# RSL15 register map
Vendor: ONSemiconductor; Series: RSL15 Series; File version: 1.0
CPU: CM33 r0p4, little endian, MPU, FPU, 3 interrupt priority bits
Registers are 32-bit, read-write, reset 0x0 unless marked. A register's access mark holds for its fields unless they carry their own. Offsets are from the block's base; [hi:lo] are bit positions.

## I2C0 — I2C Interface
Base 0x40000D00
Same registers: I2C1 0x40000E00
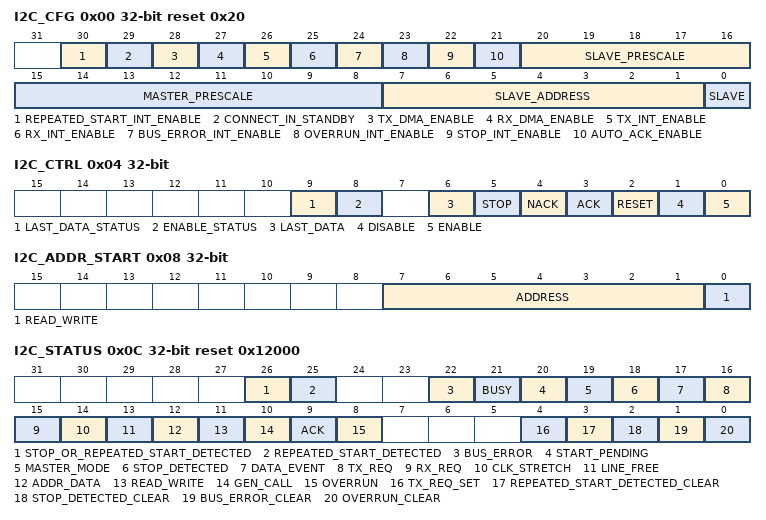
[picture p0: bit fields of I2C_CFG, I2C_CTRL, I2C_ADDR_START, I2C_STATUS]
0x00 I2C_CFG reset 0x20 — Configuration Register
  [30] REPEATED_START_INT_ENABLE — Configure whether repeated start interrupts will be generated by the I2C interface for active transactions in slave mode
    0=I2C_REPEATED_START_INT_DISABLE (Repeated start interrupts are not generated); 1=I2C_REPEATED_START_INT_ENABLE (A repeated start interrupt is generated when a repeated start condition occurs during an active transaction in slave mode)
  [29] CONNECT_IN_STANDBY — Control if the I2C lines are connected when running on the standby clock
    0=I2C_DISCONNECT_IN_STANDBY (Disconnect the I2C lines when running on standby clock); 1=I2C_CONNECT_IN_STANDBY (Keep the I2C lines connected when running on standby clock)
  [28] TX_DMA_ENABLE — Enable/disable the TX DMA request
    0=I2C_TX_DMA_DISABLE (No TX DMA request is generated); 1=I2C_TX_DMA_ENABLE (A TX DMA request is generated when new data is requested by the I2C interface)
  [27] RX_DMA_ENABLE — Enable/disable the RX DMA request
    0=I2C_RX_DMA_DISABLE (No RX DMA request is generated); 1=I2C_RX_DMA_ENABLE (An RX DMA request is generated when new data is received by the I2C interface)
  [26] TX_INT_ENABLE — Enable/disable the TX interrupt
    0=I2C_TX_INT_DISABLE (No TX interrupt is raised); 1=I2C_TX_INT_ENABLE (A TX interrupt is raised when new data is requested by the I2C interface)
  [25] RX_INT_ENABLE — Enable/disable the RX interrupt
    0=I2C_RX_INT_DISABLE (No RX interrupt is raised); 1=I2C_RX_INT_ENABLE (An RX interrupt is raised when new data is received by the I2C interface)
  [24] BUS_ERROR_INT_ENABLE — Enable/disable the bus error interrupt
    0=I2C_BUS_ERROR_INT_DISABLE (No bus error interrupt is raised when an overrun is detected); 1=I2C_BUS_ERROR_INT_ENABLE (A bus error interrupt is raised when an overrun occurs on the I2C interface)
  [23] OVERRUN_INT_ENABLE — Enable/disable the overrun interrupt
    0=I2C_OVERRUN_INT_DISABLE (No overrun interrupt is raised when an overrun is detected); 1=I2C_OVERRUN_INT_ENABLE (An overrun interrupt is raised when an overrun occurs on the I2C interface)
  [22] STOP_INT_ENABLE — Configure whether stop interrupts will be generated by the I2C interface
    0=I2C_STOP_INT_DISABLE (Stop interrupts are not generated); 1=I2C_STOP_INT_ENABLE (A stop interrupt is generated when a stop condition occurs for an active transaction)
  [21] AUTO_ACK_ENABLE — Select whether acknowledgement is automatically generated or not
    0=I2C_AUTO_ACK_DISABLE (Require manual acknowledgement of all I2C interface transfers); 1=I2C_AUTO_ACK_ENABLE (Use automatic acknowledgement for I2C interface transfers)
  [20:16] SLAVE_PRESCALE — Controls the number of SYSCLK wait cycles in case of clock streching (in slave mode) between the moment the data is put on the SDA line and the SCL line is released.
    0=I2C_SLAVE_PRESCALE_1 (Slave Standard-mode: at least 250 ns +10 percent data set-up time with SYSCLK = 3 MHz; Slave Fast-mode: at least 100 ns +10 percent data set-up time with SYSCLK = 3, 4, 5, 8 MHz; Slave Fast-mode Plus: at least 50 ns +10 percent data set-up time with SYSCLK = 3, 4, 5, 8, 10, 12, 16 MHz); 1=I2C_SLAVE_PRESCALE_2 (Slave Standard-Mode: at least 250 ns +10 percent data set-up time with SYSCLK = 4, 5 MHz; Slave Fast-Mode: at least 100 ns +10 percent data set-up time with SYSCLK = 10, 12, 16 MHz; Slave Fast-mode Plus: at least 50 ns +10 percent data set-up time with SYSCLK = 20, 24 MHz); 2=I2C_SLAVE_PRESCALE_3 (Slave Standard-Mode: at least 250 ns +10 percent data set-up time with SYSCLK = 8, 10 MHz; Slave Fast-Mode: at least 100 ns +10 percent data set-up time with SYSCLK = 20, 24 MHz; Slave Fast-mode Plus: at least 50 ns +10 percent data set-up time with SYSCLK = 48 MHz); 3=I2C_SLAVE_PRESCALE_4 (Slave Standard-Mode: at least 250 ns +10 percent data set-up time with SYSCLK = 12 MHz); 4=I2C_SLAVE_PRESCALE_5 (Slave Standard-Mode: at least 250 ns +10 percent data set-up time with SYSCLK = 16 MHz); 5=I2C_SLAVE_PRESCALE_6 (Slave Standard-Mode: at least 250 ns +10 percent data set-up time with SYSCLK = 20 MHz; Slave Fast-Mode: at least 100 ns +10 percent data set-up time with SYSCLK = 48 MHz); 6=I2C_SLAVE_PRESCALE_7 (Slave Standard-Mode: at least 250 ns +10 percent data set-up time with SYSCLK = 24 MHz); 13=I2C_SLAVE_PRESCALE_14 (Slave Standard-Mode: at least 250 ns +10 percent data set-up time with SYSCLK = 48 MHz); 31=I2C_SLAVE_PRESCALE_32 (Maximum number of clock stretching cycles between SDA output and SCL release)
  [15:8] MASTER_PRESCALE — Prescaler used to divide SYSCLK to the correct SCL frequency when operating in master mode. SCL is prescaled by (PRESCALE + 1) * 3.
    0=I2C_MASTER_PRESCALE_3 (Master mode: prescale SCL from SYSCLK by 3); 1=I2C_MASTER_PRESCALE_6 (Master mode: prescale SCL from SYSCLK by 6); 2=I2C_MASTER_PRESCALE_9 (Master mode: prescale SCL from SYSCLK by 9); 3=I2C_MASTER_PRESCALE_12 (Master mode: prescale SCL from SYSCLK by 12); 4=I2C_MASTER_PRESCALE_15 (Master mode: prescale SCL from SYSCLK by 15); 5=I2C_MASTER_PRESCALE_18 (Master mode: prescale SCL from SYSCLK by 18); 6=I2C_MASTER_PRESCALE_21 (Master mode: prescale SCL from SYSCLK by 21); 7=I2C_MASTER_PRESCALE_24 (Master mode: prescale SCL from SYSCLK by 24); 8=I2C_MASTER_PRESCALE_27 (Master mode: prescale SCL from SYSCLK by 27); 9=I2C_MASTER_PRESCALE_30 (Master mode: prescale SCL from SYSCLK by 30); 10=I2C_MASTER_PRESCALE_33 (Master mode: prescale SCL from SYSCLK by 33); 11=I2C_MASTER_PRESCALE_36 (Master mode: prescale SCL from SYSCLK by 36); 12=I2C_MASTER_PRESCALE_39 (Master mode: prescale SCL from SYSCLK by 39); 13=I2C_MASTER_PRESCALE_42 (Master mode: prescale SCL from SYSCLK by 42); 14=I2C_MASTER_PRESCALE_45 (Master mode: prescale SCL from SYSCLK by 45); 15=I2C_MASTER_PRESCALE_48 (Master mode: prescale SCL from SYSCLK by 48); 16=I2C_MASTER_PRESCALE_51 (Master mode: prescale SCL from SYSCLK by 51); 17=I2C_MASTER_PRESCALE_54 (Master mode: prescale SCL from SYSCLK by 54); 18=I2C_MASTER_PRESCALE_57 (Master mode: prescale SCL from SYSCLK by 57); 19=I2C_MASTER_PRESCALE_60 (Master mode: prescale SCL from SYSCLK by 60); 39=I2C_MASTER_PRESCALE_120 (Master mode: prescale SCL from SYSCLK by 120); 255=I2C_MASTER_PRESCALE_768 (Master mode: prescale SCL from SYSCLK by 768)
  [7:1] SLAVE_ADDRESS — Set the I2C slave address for this device
  [0] SLAVE — Select whether the I2C interface is enabled for slave mode or not
    0=I2C_SLAVE_DISABLE (Disable I2C interface slave mode operation); 1=I2C_SLAVE_ENABLE (Enable I2C interface slave mode operation)
0x04 I2C_CTRL (reset mask 0x300) — Control Register
  [9] LAST_DATA_STATUS ro — I2C last data status
    0=I2C_LAST_DATA_DISABLED (I2C last data is disabled); 1=I2C_LAST_DATA_ENABLED (I2C last data is enabled)
  [8] ENABLE_STATUS ro — I2C enable status
    0=I2C_STATUS_DISABLED (I2C interface is disabled); 1=I2C_STATUS_ENABLED (I2C interface is enabled)
  [6] LAST_DATA wo — Indicate that the current data is the last byte of a data transfer
    1=I2C_LAST_DATA (Indicate that the current data is the last byte of a data transfer)
  [5] STOP wo — Issue a stop condition on the I2C interface bus
    1=I2C_STOP (Issue a stop condition on the I2C interface bus)
  [4] NACK wo — Issue a not acknowledge on the I2C interface bus
    1=I2C_NACK (Issue a not acknowledge on the I2C interface bus)
  [3] ACK wo — Issue an acknowledge on the I2C interface bus
    1=I2C_ACK (Issue an acknowledge on the I2C interface bus); 1=I2C_RESUME (Resume I2C interface after receiving address ACK/NACK in master read auto ack disable mode)
  [2] RESET wo — Reset the I2C interface
    1=I2C_RESET (Reset the I2C interface)
  [1] DISABLE wo — Disable the I2C interface
    1=I2C_DISABLE (Disable the I2C interface)
  [0] ENABLE wo — Enable the I2C interface
    1=I2C_ENABLE (Enable the I2C interface)
0x08 I2C_ADDR_START — Master Address and Start Register
  [7:1] ADDRESS — I2C address to use for the transaction
  [0] READ_WRITE — Select whether a read or a write transaction is started
    0=I2C_START_WRITE (Start an I2C write transaction); 1=I2C_START_READ (Start an I2C read transaction)
0x0C I2C_STATUS reset 0x12000 (reset mask 0x67FFF00) — Status Register
  [26] STOP_OR_REPEATED_START_DETECTED ro — Indicate if STOP_DETECTED or REPEATED_START_DETECTED bit is set
    0=I2C_STOP_NOR_REPEATED_START_DETECTED (Neither STOP_DETECTED nor REPEATED_START_DETECTED bits are set); 1=I2C_STOP_OR_REPEATED_START_DETECTED (STOP_DETECTED or REPEATED_START_DETECTED bit is set)
  [25] REPEATED_START_DETECTED ro — Indicate if an I2C repeated start has been detected during an active transaction in slave mode
    0=I2C_NO_REPEATED_START_DETECTED (No repeated start condition has been detected on the I2C bus during an active transaction in slave mode); 1=I2C_REPEATED_START_DETECTED (A repeated start condition has been detected on the I2C bus during an active transaction in slave mode)
  [22] BUS_ERROR ro — Bus error status bit
    0=I2C_NO_BUS_ERROR (No I2C bus error has occurred); 1=I2C_BUS_ERROR (An I2C bus error has occurred)
  [21] BUSY ro — Indicate that the reception or transmission of the data is ongoing
    0=I2C_IDLE (I2C interface is idle); 1=I2C_BUSY (I2C interface is busy)
  [20] START_PENDING ro — Master frame start pending status bit
    0=I2C_START_NOT_PENDING (No pending master start frame); 1=I2C_START_PENDING (A master frame is pending to start (bit is set when I2C_ADDR_START is written))
  [19] MASTER_MODE ro — Master mode status bit
    0=I2C_MASTER_INACTIVE (I2C interface is not operating in master mode); 1=I2C_MASTER_ACTIVE (I2C interface is operating in master mode)
  [18] STOP_DETECTED ro — Indicate if an I2C stop bit has been detected
    0=I2C_NO_STOP_DETECTED (No stop condition has been detected on the I2C bus); 1=I2C_STOP_DETECTED (A stop condition has been detected on the I2C bus)
  [17] DATA_EVENT ro — Indicate that I2C interface either needs data to transmit or has received data
    0=I2C_NON_DATA_EVENT (No I2C data is needed or available); 1=I2C_DATA_EVENT (I2C data is needed or is available)
  [16] TX_REQ ro — Indicate that a TX data can be written
    0=I2C_TX_NO_REQ (I2C TX data has already been written); 1=I2C_TX_REQ (I2C TX data can be written)
  [15] RX_REQ ro — Indicate that a RX data can be read
    0=I2C_RX_NO_REQ (No new I2C RX data available); 1=I2C_RX_REQ (New I2C RX data available)
  [14] CLK_STRETCH ro — Clock stretching flag
    0=I2C_CLK_NOT_STRETCHED (I2C interface is currently not clock streching); 1=I2C_CLK_STRETCHED (I2C interface is currently clock streching)
  [13] LINE_FREE ro — Line free flag
    0=I2C_BUS_BUSY (I2C transaction ongoing); 1=I2C_BUS_FREE (I2C bus is free)
  [12] ADDR_DATA ro — Address / Data byte
    0=I2C_DATA_IS_DATA (The I2C data register holds data); 1=I2C_DATA_IS_ADDR (The I2C data register holds an address)
  [11] READ_WRITE ro — Read / Write frame
    0=I2C_IS_WRITE (The current I2C transfer is a write); 1=I2C_IS_READ (The current I2C transfer is a read)
  [10] GEN_CALL ro — General call flag
    0=I2C_ADDR_OTHER (The address used for the current I2C transfer is not the general call address); 1=I2C_ADDR_GEN_CALL (The address used for the current I2C transfer is the general call address)
  [9] ACK ro — Acknowledge status
    0=I2C_HAS_ACK (Indicate that the last I2C byte was acknowledged); 1=I2C_HAS_NACK (Indicate that the last I2C byte was not acknowledged)
  [8] OVERRUN ro — Indicate that an overrun has occurred when receiving data
    0=I2C_OVERRUN_FALSE (No I2C input overrun detected); 1=I2C_OVERRUN_TRUE (I2C input overrun detected)
  [4] TX_REQ_SET wo — Set TX_REQ status flag
    1=I2C_TX_REQ_SET (Set the TX_REQ status flag)
  [3] REPEATED_START_DETECTED_CLEAR wo — Clear REPEATED_START_DETECTED status flag
    1=I2C_REPEATED_START_DETECTED_CLEAR (Clear the REPEATED_START_DETECTED status flag)
  [2] STOP_DETECTED_CLEAR wo — Clear STOP_DETECTED status flag
    1=I2C_STOP_DETECTED_CLEAR (Clear the STOP_DETECTED status flag)
  [1] BUS_ERROR_CLEAR wo — Clear BUS_ERROR status flag
    1=I2C_BUS_ERROR_CLEAR (Clear the BUS_ERROR status flag)
  [0] OVERRUN_CLEAR wo — Clear OVERRUN status flag
    1=I2C_OVERRUN_CLEAR (Clear the OVERRUN status flag)
0x10 I2C_TX_DATA — Transmit Data Register
  [7:0] TX_DATA — Single byte buffer for data transmitted over the I2C interface
0x14 I2C_RX_DATA ro — Receive Data Register
  [7:0] RX_DATA — Single byte buffer for data received over the I2C interface
0x18 I2C_RX_DATA_MIRROR access not given (reset mask 0xFF) — Receive Data Mirror Register
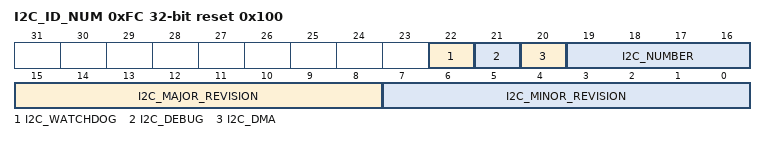
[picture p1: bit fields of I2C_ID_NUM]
0xFC I2C_ID_NUM ro reset 0x100 — I2C ID number
  [22] I2C_WATCHDOG — Implementation of the watchdog counter
    0=I2C_WATCHDOG_DISABLED (Watchdog counter is not implemented); 1=I2C_WATCHDOG_ENABLED (Watchdog counter is implemented)
  [21] I2C_DEBUG — Implementation of the debug interface
    0=I2C_DEBUG_DISABLED (Debug interface is not implemented); 1=I2C_DEBUG_ENABLED (Debug interface is implemented)
  [20] I2C_DMA — Implementation of the DMA interface
    0=I2C_DMA_DISABLED (DMA interface is not implemented); 1=I2C_DMA_ENABLED (DMA interface is implemented)
  [19:16] I2C_NUMBER — I2C instance number
  [15:8] I2C_MAJOR_REVISION — I2C Major Revision number
    1=I2C_MAJOR_REVISION (I2C revision 1.0)
  [7:0] I2C_MINOR_REVISION — I2C Minor Revision number
    0=I2C_MINOR_REVISION (I2C revision 1.0)
